# MSP432E401Y register map
Vendor: Texas Instruments; Series: MSP432E4; File version: 3.200
CPU: CM4 r1p2, little endian, no MPU, FPU, 3 interrupt priority bits
Registers are 32-bit, read-write, no defined reset value unless marked. A register's access mark holds for its fields unless they carry their own. Offsets are from the block's base; [hi:lo] are bit positions; {n}, {i} and the like mark numbered series.

## GPIOA — Register map for GPIOA peripheral
Base 0x40058000; register names take the prefix GPIOA
Same registers: GPIOB 0x40059000 (register names take the prefix GPIOB), GPIOC 0x4005A000 (register names take the prefix GPIOC), GPIOD 0x4005B000 (register names take the prefix GPIOD), GPIOE 0x4005C000 (register names take the prefix GPIOE), GPIOF 0x4005D000 (register names take the prefix GPIOF), GPIOG 0x4005E000 (register names take the prefix GPIOG), GPIOH 0x4005F000 (register names take the prefix GPIOH), GPIOJ 0x40060000 (register names take the prefix GPIOJ), GPIOK 0x40061000 (register names take the prefix GPIOK), GPIOL 0x40062000 (register names take the prefix GPIOL), GPIOM 0x40063000 (register names take the prefix GPIOM), GPION 0x40064000 (register names take the prefix GPION), GPIOP 0x40065000 (register names take the prefix GPIOP), GPIOQ 0x40066000 (register names take the prefix GPIOQ)
0x3FC DATA — GPIO Data
0x400 DIR — GPIO Direction
0x404 IS — GPIO Interrupt Sense
0x408 IBE — GPIO Interrupt Both Edges
0x40C IEV — GPIO Interrupt Event
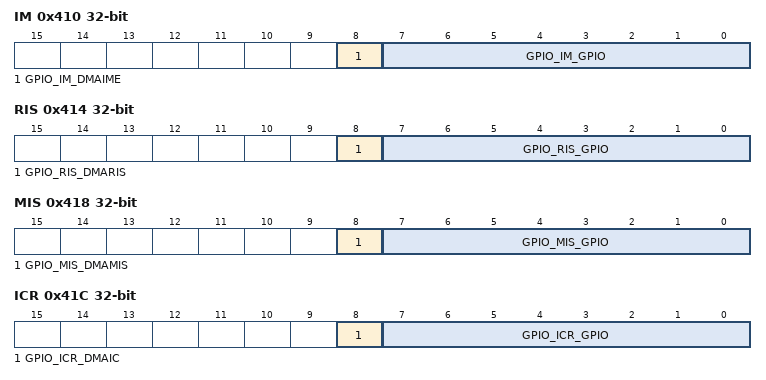
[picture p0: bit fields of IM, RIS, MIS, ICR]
0x410 IM — GPIO Interrupt Mask
  [8] GPIO_IM_DMAIME — GPIO uDMA Done Interrupt Mask Enable
  [7:0] GPIO_IM_GPIO — GPIO Interrupt Mask Enable
0x414 RIS — GPIO Raw Interrupt Status
  [8] GPIO_RIS_DMARIS — GPIO uDMA Done Interrupt Raw Status
  [7:0] GPIO_RIS_GPIO — GPIO Interrupt Raw Status
0x418 MIS — GPIO Masked Interrupt Status
  [8] GPIO_MIS_DMAMIS — GPIO uDMA Done Masked Interrupt Status
  [7:0] GPIO_MIS_GPIO — GPIO Masked Interrupt Status
0x41C ICR wo — GPIO Interrupt Clear
  [8] GPIO_ICR_DMAIC — GPIO uDMA Interrupt Clear
  [7:0] GPIO_ICR_GPIO — GPIO Interrupt Clear
0x420 AFSEL — GPIO Alternate Function Select
0x500 DR2R — GPIO 2-mA Drive Select
0x504 DR4R — GPIO 4-mA Drive Select
0x508 DR8R — GPIO 8-mA Drive Select
0x50C ODR — GPIO Open Drain Select
0x510 PUR — GPIO Pull-Up Select
0x514 PDR — GPIO Pull-Down Select
0x518 SLR — GPIO Slew Rate Control Select
0x51C DEN — GPIO Digital Enable
0x520 LOCK — GPIO Lock
  [31:0] GPIO_LOCK
    0=GPIO_LOCK_UNLOCKED (The GPIOCR register is unlocked and may be modified); 1=GPIO_LOCK_LOCKED (The GPIOCR register is locked and may not be modified)
0x524 CR — GPIO Commit
0x528 AMSEL — GPIO Analog Mode Select
0x52C PCTL — GPIO Port Control
0x530 ADCCTL — GPIO ADC Control
0x534 DMACTL — GPIO DMA Control
0x538 SI — GPIO Select Interrupt
  [0] GPIO_SI_SUM — Summary Interrupt
0x53C DR12R — GPIO 12-mA Drive Select
  [7:0] GPIO_DR12R_DRV12 — Output Pad 12-mA Drive Enable
    1=GPIO_DR12R_DRV12_12MA (The corresponding GPIO pin has 12-mA drive. This encoding is only valid if the GPIOPP EDE bit is set and the appropriate GPIOPC EDM bit field is programmed to 0x3)
0x540 WAKEPEN — GPIO Wake Pin Enable
  [4] GPIO_WAKEPEN_WAKEP4 — P[4] Wake Enable
0x544 WAKELVL — GPIO Wake Level
  [4] GPIO_WAKELVL_WAKELVL4 — P[4] Wake Level
0x548 WAKESTAT — GPIO Wake Status
  [4] GPIO_WAKESTAT_STAT4 — P[4] Wake Status
0xFC0 PP — GPIO Peripheral Property
  [0] GPIO_PP_EDE — Extended Drive Enable
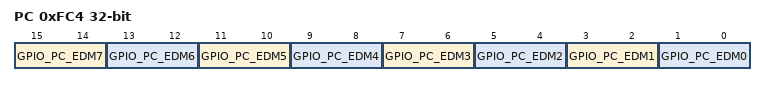
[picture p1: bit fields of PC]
0xFC4 PC — GPIO Peripheral Configuration
  [2n+1:2n] GPIO_PC_EDM{n} (n=1..7) — Extended Drive Mode Bit {n}
  [1:0] GPIO_PC_EDM0 — Extended Drive Mode Bit 0
    0=GPIO_PC_EDM0_DISABLE (Drive values of 2, 4 and 8 mA are maintained. GPIO n Drive Select (GPIODRnR) registers function as normal); 1=GPIO_PC_EDM0_6MA (An additional 6 mA option is provided); 3=GPIO_PC_EDM0_PLUS2MA (A 2 mA driver is always enabled; setting the corresponding GPIODR4R register bit adds 2 mA and setting the corresponding GPIODR8R of GPIODR12R register bit adds an additional 4 mA)

## EEPROM — Register map for EEPROM peripheral
Base 0x400AF000; register names take the prefix EEPROM
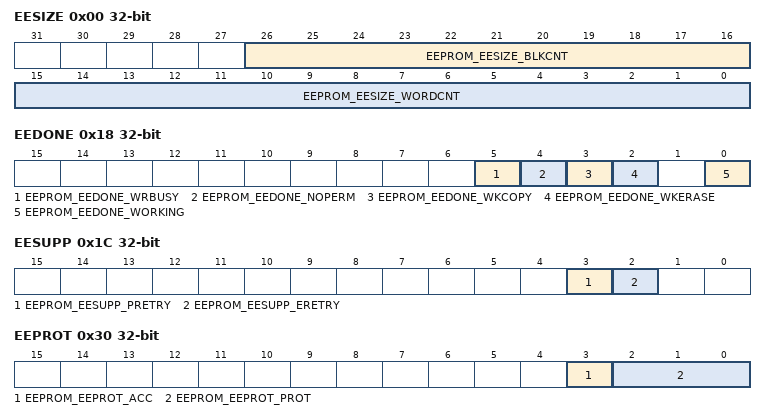
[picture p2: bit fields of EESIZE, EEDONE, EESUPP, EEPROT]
0x00 EESIZE — EEPROM Size Information
  [26:16] EEPROM_EESIZE_BLKCNT — Number of 16-Word Blocks
  [15:0] EEPROM_EESIZE_WORDCNT — Number of 32-Bit Words
0x04 EEBLOCK — EEPROM Current Block
  [15:0] EEPROM_EEBLOCK_BLOCK — Current Block
0x08 EEOFFSET — EEPROM Current Offset
  [3:0] EEPROM_EEOFFSET_OFFSET — Current Address Offset
0x10 EERDWR — EEPROM Read-Write
  [31:0] EEPROM_EERDWR_VALUE — EEPROM Read or Write Data
0x14 EERDWRINC — EEPROM Read-Write with Increment
  [31:0] EEPROM_EERDWRINC_VALUE — EEPROM Read or Write Data with Increment
0x18 EEDONE — EEPROM Done Status
  [5] EEPROM_EEDONE_WRBUSY — Write Busy
  [4] EEPROM_EEDONE_NOPERM — Write Without Permission
  [3] EEPROM_EEDONE_WKCOPY — Working on a Copy
  [2] EEPROM_EEDONE_WKERASE — Working on an Erase
  [0] EEPROM_EEDONE_WORKING — EEPROM Working
0x1C EESUPP — EEPROM Support Control and Status
  [3] EEPROM_EESUPP_PRETRY — Programming Must Be Retried
  [2] EEPROM_EESUPP_ERETRY — Erase Must Be Retried
0x20 EEUNLOCK — EEPROM Unlock
  [31:0] EEPROM_EEUNLOCK_UNLOCK
0x30 EEPROT — EEPROM Protection
  [3] EEPROM_EEPROT_ACC — Access Control
  [2:0] EEPROM_EEPROT_PROT — Protection Control
    0=EEPROM_EEPROT_PROT_RWNPW (This setting is the default. If there is no password, the block is not protected and is readable and writable); 1=EEPROM_EEPROT_PROT_RWPW (If there is a password, the block is readable or writable only when unlocked); 2=EEPROM_EEPROT_PROT_RONPW (If there is no password, the block is readable, not writable)
{0x34+4i} EEPASS{i} (i=0..2) — EEPROM Password
  [31:0] EEPROM_EEPASS{i}_PASS — Password
0x40 EEINT — EEPROM Interrupt
  [0] EEPROM_EEINT_INT — Interrupt Enable
0x50 EEHIDE0 — EEPROM Block Hide 0
  [31:1] EEPROM_EEHIDE0_HN — Hide Block
0x54 EEHIDE1 — EEPROM Block Hide 1
  [31:0] EEPROM_EEHIDE1_HN — Hide Block
0x58 EEHIDE2 — EEPROM Block Hide 2
  [31:0] EEPROM_EEHIDE2_HN — Hide Block
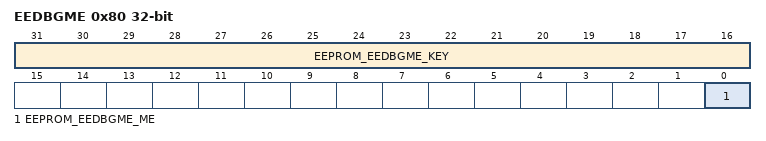
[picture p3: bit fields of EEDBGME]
0x80 EEDBGME — EEPROM Debug Mass Erase
  [31:16] EEPROM_EEDBGME_KEY — Erase Key
  [0] EEPROM_EEDBGME_ME — Mass Erase
0xFC0 PP — EEPROM Peripheral Properties
  [15:0] EEPROM_PP_SIZE — EEPROM Size

## Notices in the file
Software License Agreement
Texas Instruments (TI) is supplying this software for use solely and
exclusively on TI's microcontroller products. The software is owned by
TI and/or its suppliers, and is protected under applicable copyright
laws. You may not combine this software with "viral" open-source
software in order to form a larger program.
THIS SOFTWARE IS PROVIDED "AS IS" AND WITH ALL FAULTS.
NO WARRANTIES, WHETHER EXPRESS, IMPLIED OR STATUTORY, INCLUDING, BUT
NOT LIMITED TO, IMPLIED WARRANTIES OF MERCHANTABILITY AND FITNESS FOR
A PARTICULAR PURPOSE APPLY TO THIS SOFTWARE. TI SHALL NOT, UNDER ANY
CIRCUMSTANCES, BE LIABLE FOR SPECIAL, INCIDENTAL, OR CONSEQUENTIAL
DAMAGES, FOR ANY REASON WHATSOEVER.
